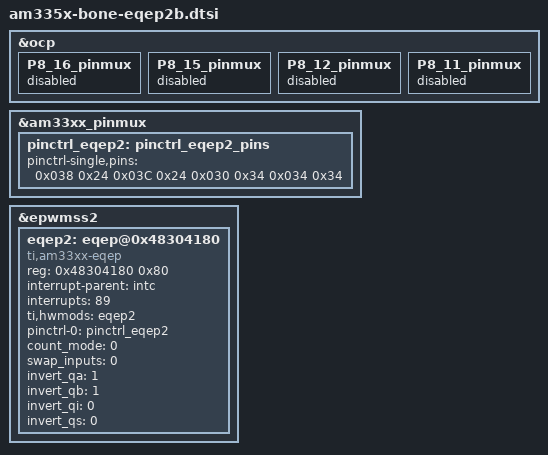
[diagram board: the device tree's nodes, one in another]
/*
 * Copyright (C) 2013 Nathaniel R. Lewis - http://nathanielrlewis.com/
 *
 * This program is free software; you can redistribute it and/or modify
 * it under the terms of the GNU General Public License version 2 as
 * published by the Free Software Foundation.
 * 
 * Enable eQEP2 on the Beaglebone White and Black
 * These pins don't conflict with the HDMI
 */

&ocp {
	P8_16_pinmux {
		status = "disabled";
	};
	P8_15_pinmux {
		status = "disabled";
	};
	P8_12_pinmux {
		status = "disabled";
	};
	P8_11_pinmux {
		status = "disabled";
	};
};

&am33xx_pinmux {
	pinctrl_eqep2: pinctrl_eqep2_pins {
		pinctrl-single,pins = <
      0x038 0x24//(PIN_INPUT_PULLDOWN | MUX_MODE4)  /* P8_16 = GPIO1_14 = EQEP2_index, MODE4 */
      0x03C 0x24//(PIN_INPUT_PULLDOWN | MUX_MODE4)  /* P8_15 = GPIO1_15 = EQEP2_strobe, MODE4 */
      0x030 0x34//(PIN_INPUT_PULLDOWN | MUX_MODE4)  /* P8_12 = GPIO1_12 = EQEP2A_in, MODE4 */
      0x034 0x34//(PIN_INPUT_PULLDOWN | MUX_MODE4)  /* P8_11 = GPIO1_13 = EQEP2B_in, MODE4 */
		>;
	};
};

&epwmss2 {
  status = "okay";

  eqep2: eqep@0x48304180 {
    compatible = "ti,am33xx-eqep";
    reg = <0x48304180 0x80>;
    interrupt-parent = <&intc>;
    interrupts = <89>;
    ti,hwmods = "eqep2";
    status = "okay";

    pinctrl-names = "default";
    pinctrl-0 = <&pinctrl_eqep2>;
    
    count_mode = <0>;  /* 0 - Quadrature mode, normal 90 phase offset cha & chb.  1 - Direction mode.  cha input = clock, chb input = direction */
    swap_inputs = <0>; /* Are channel A and channel B swapped? (0 - no, 1 - yes) */
    invert_qa = <1>;   /* Should we invert the channel A input?  */
    invert_qb = <1>;   /* Should we invert the channel B input? I invert these because my encoder outputs drive transistors that pull down the pins */
    invert_qi = <0>;   /* Should we invert the index input? */
    invert_qs = <0>;   /* Should we invert the strobe input? */
  };
};
